# MKM38Z5 register map
File version: 1.6
Registers are 8-bit, read-write, reset 0x0 unless marked. A register's access mark holds for its fields unless they carry their own. Offsets are from the block's base; [hi:lo] are bit positions; {n}, {i} and the like mark numbered series; 'fields as' and 'values as' point back to an identical list.

## ROM — System ROM
Base 0xF0002000; register names take the prefix ROM_
{0x0+4i} ENTRY{i} (i=0..2) 32-bit ro reset not defined
  [31:0] ENTRY
0x0C TABLEMARK 32-bit ro — End of Table Marker Register
  [31:0] MARK
0xFCC SYSACCESS 32-bit ro reset 0x1 — System Access Register
0xFD0 PERIPHID{x} (x=4,5,6,7,0,1,2,3; step 0x4) 32-bit ro reset not defined — Peripheral ID Register
  [31:0] PERIPHID
{0xFF0+4i} COMPID{i} (i=0..3) 32-bit ro reset not defined — Component ID Register
  [31:0] COMPID — Component ID

## MCM — Core Platform Miscellaneous Control Module
Base 0xF0003000; register names take the prefix MCM_
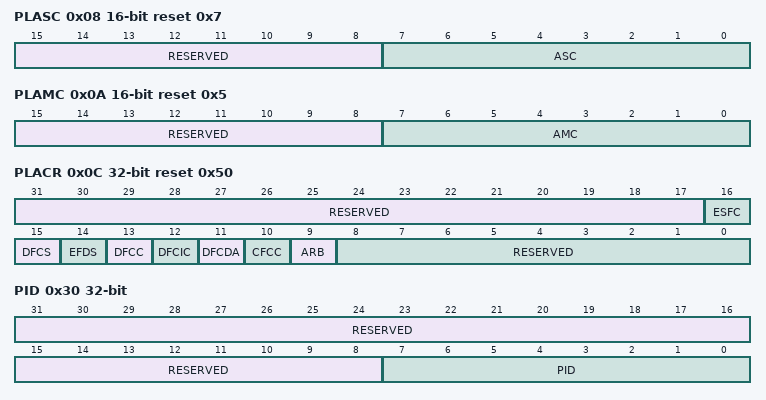
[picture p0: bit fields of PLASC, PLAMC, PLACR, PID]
0x08 PLASC 16-bit ro reset 0x7 — Crossbar Switch (AXBS) Slave Configuration
  [15:8] RESERVED
  [7:0] ASC — Each bit in the ASC field indicates whether there is a corresponding connection to the crossbar switch's slave input port.
    0=A bus slave connection to AXBS input port n is absent; 1=A bus slave connection to AXBS input port n is present
0x0A PLAMC 16-bit ro reset 0x5 — Crossbar Switch (AXBS) Master Configuration
  [15:8] RESERVED
  [7:0] AMC — Each bit in the AMC field indicates whether there is a corresponding connection to the AXBS master input port.
    0=A bus master connection to AXBS input port n is absent; 1=A bus master connection to AXBS input port n is present
0x0C PLACR 32-bit reset 0x50 — Platform Control Register
  [31:17] RESERVED ro
  [16] ESFC — Enable Stalling Flash Controller
    0=Disable stalling flash controller when flash is busy; 1=Enable stalling flash controller when flash is busy
  [15] DFCS — Disable Flash Controller Speculation
    0=Enable flash controller speculation; 1=Disable flash controller speculation
  [14] EFDS — Enable Flash Data Speculation
    0=Disable flash data speculation; 1=Enable flash data speculation
  [13] DFCC — Disable Flash Controller Cache
    0=Enable flash controller cache; 1=Disable flash controller cache
  [12] DFCIC — Disable Flash Controller Instruction Caching
    0=Enable flash controller instruction caching; 1=Disable flash controller instruction caching
  [11] DFCDA — Disable Flash Controller Data Caching
    0=Enable flash controller data caching; 1=Disable flash controller data caching
  [10] CFCC wo — Clear Flash Controller Cache
  [9] ARB — Arbitration select
    0=Fixed-priority arbitration for the crossbar masters; 1=Round-robin arbitration for the crossbar masters
  [8:0] RESERVED ro
0x30 PID 32-bit — Process ID register
  [31:8] RESERVED ro
  [7:0] PID — M0_PID For MPU
    0=Reserved for privileged secure tasks
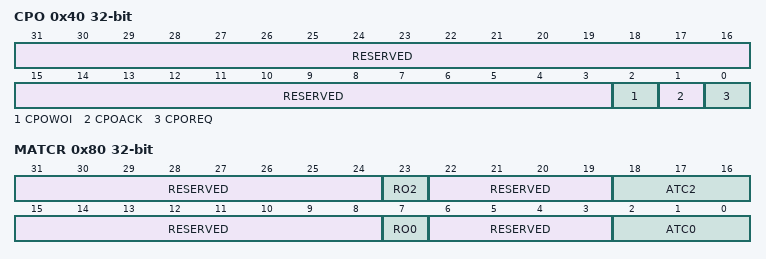
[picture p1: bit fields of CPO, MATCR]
0x40 CPO 32-bit — Compute Operation Control Register
  [31:3] RESERVED ro
  [2] CPOWOI — Compute Operation wakeup on interrupt
    0=No effect; 1=When set, the CPOREQ is cleared on any interrupt or exception vector fetch
  [1] CPOACK ro — Compute Operation acknowledge
    0=Compute operation entry has not completed or compute operation exit has completed; 1=Compute operation entry has completed or compute operation exit has not completed
  [0] CPOREQ — Compute Operation request
    0=Request is cleared; 1=Request Compute Operation
0x80 MATCR 32-bit — Master Attribute Configuration Register
  [31:24] RESERVED ro
  [23] RO2 — Read-Only Master n
    0=Writes to the ATCn are allowed; 1=Writes to the ATCn are ignored
  [22:19] RESERVED ro
  [18:16] ATC2 — Attribute Configuration Master n
    0b00x=Master attributes are statically forced to {privileged, secure}; 2=Master attributes are statically forced to {user, secure}; 3=Master attributes are statically forced to {user, nonsecure}; 4=Enable master attribute {privileged or user} and statically force {secure}; 5=Enable master attribute {privileged or user} and statically force {nonsecure}; 0b11x=Enable master attribute {privileged or user, secure or nonsecure}
  [15:8] RESERVED ro
  [7] RO0 — Read-Only Master n
    values as RO2
  [6:3] RESERVED ro
  [2:0] ATC0 — Attribute Configuration Master n
    values as ATC2
